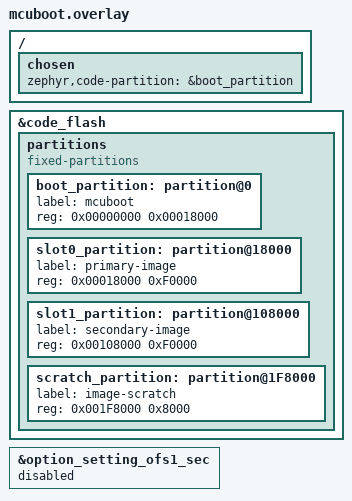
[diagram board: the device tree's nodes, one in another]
/ {
    chosen {
        zephyr,code-partition = &boot_partition;
    };
};
&code_flash {
        partitions {
                compatible = "fixed-partitions";
                #address-cells = <1>;
                #size-cells = <1>;
                boot_partition: partition@0 {
                        label = "mcuboot";
                        reg = <0x00000000 0x00018000>;
                };
                slot0_partition: partition@18000 {
                        label = "primary-image";
                        reg = <0x00018000 0xF0000>;
                };
                slot1_partition: partition@108000 {
                        label = "secondary-image";
                        reg = <0x00108000 0xF0000>;
                };
                scratch_partition: partition@1F8000 {
                        label = "image-scratch";
                        reg = <0x001F8000 0x8000>;
                };
        };
};

&option_setting_ofs1_sec {
	status = "disabled";
};
